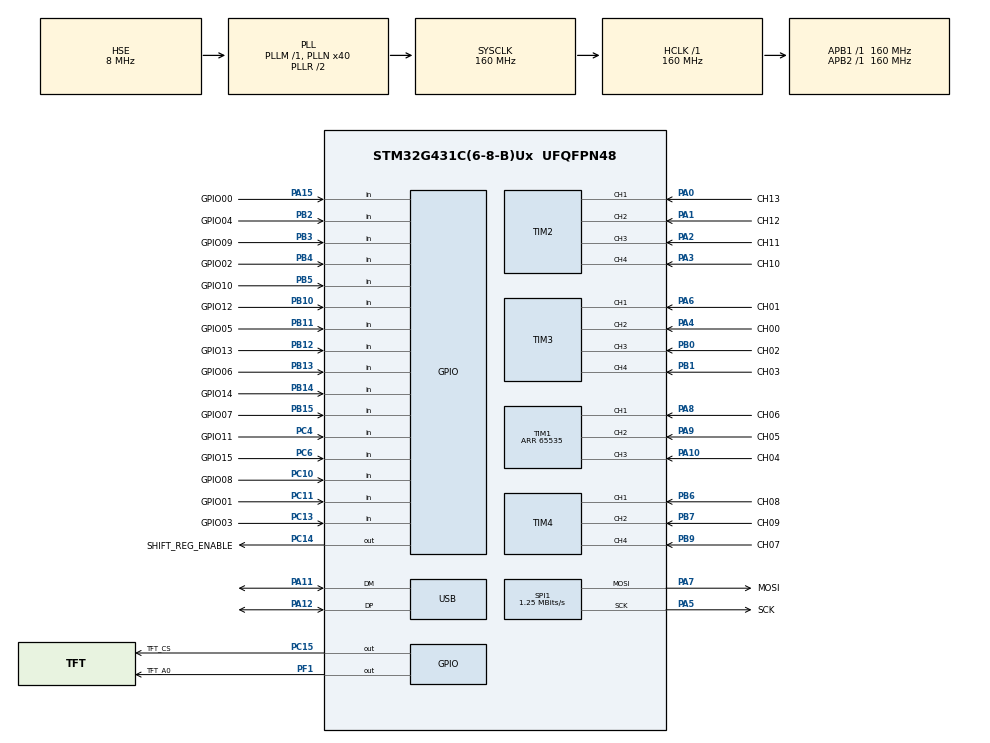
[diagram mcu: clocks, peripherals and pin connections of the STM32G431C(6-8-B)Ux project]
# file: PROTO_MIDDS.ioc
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Mcu.Family=STM32G4
Mcu.Name=STM32G431C(6-8-B)Ux
Mcu.Package=UFQFPN48
NVIC.PriorityGroup=NVIC_PRIORITYGROUP_4
NVIC.TIM1_CC_IRQn=true\:0\:0\:true\:true\:true\:2\:true\:true\:true
NVIC.TIM1_UP_TIM16_IRQn=true\:0\:0\:true\:true\:true\:1\:true\:true\:true
NVIC.TIM2_IRQn=true\:0\:0\:false\:false\:true\:true\:true\:true
NVIC.TIM3_IRQn=true\:0\:0\:false\:false\:true\:true\:true\:true
NVIC.TIM4_IRQn=true\:0\:0\:false\:false\:true\:true\:true\:true
NVIC.USB_LP_IRQn=true\:0\:0\:false\:false\:true\:false\:true\:true
PA0.GPIO_Label=CH13
PA0.GPIO_PuPd=GPIO_PULLDOWN
PA0.GPIO_Speed=GPIO_SPEED_FREQ_VERY_HIGH
PA0.Signal=S_TIM2_CH1
PA1.GPIO_Label=CH12
PA1.GPIO_PuPd=GPIO_PULLDOWN
PA1.GPIO_Speed=GPIO_SPEED_FREQ_VERY_HIGH
PA1.Signal=S_TIM2_CH2
PA10.GPIO_Label=CH04
PA10.GPIO_PuPd=GPIO_PULLDOWN
PA10.GPIO_Speed=GPIO_SPEED_FREQ_VERY_HIGH
PA10.Signal=S_TIM1_CH3
PA11.Mode=Device
PA11.Signal=USB_DM
PA12.Mode=Device
PA12.Signal=USB_DP
PA15.GPIO_Label=GPIO00
PA15.Signal=GPIO_Input
PA2.GPIO_Label=CH11
PA2.GPIO_PuPd=GPIO_PULLDOWN
PA2.GPIO_Speed=GPIO_SPEED_FREQ_VERY_HIGH
PA2.Signal=S_TIM2_CH3
PA3.GPIO_Label=CH10
PA3.GPIO_PuPd=GPIO_PULLDOWN
PA3.GPIO_Speed=GPIO_SPEED_FREQ_VERY_HIGH
PA3.Signal=S_TIM2_CH4
PA4.GPIO_Label=CH00
PA4.GPIO_PuPd=GPIO_PULLDOWN
PA4.GPIO_Speed=GPIO_SPEED_FREQ_VERY_HIGH
PA4.Signal=S_TIM3_CH2
PA5.GPIO_Label=SCK
PA5.GPIO_Speed=GPIO_SPEED_FREQ_VERY_HIGH
PA5.Mode=TX_Only_Simplex_Unidirect_Master
PA5.Signal=SPI1_SCK
PA6.GPIO_Label=CH01
PA6.GPIO_PuPd=GPIO_PULLDOWN
PA6.GPIO_Speed=GPIO_SPEED_FREQ_VERY_HIGH
PA6.Signal=S_TIM3_CH1
PA7.GPIO_Label=MOSI
PA7.Mode=TX_Only_Simplex_Unidirect_Master
PA7.Signal=SPI1_MOSI
PA8.GPIO_Label=CH06
PA8.GPIO_PuPd=GPIO_PULLDOWN
PA8.GPIO_Speed=GPIO_SPEED_FREQ_VERY_HIGH
PA8.Signal=S_TIM1_CH1
PA9.GPIO_Label=CH05
PA9.GPIO_PuPd=GPIO_PULLDOWN
PA9.GPIO_Speed=GPIO_SPEED_FREQ_VERY_HIGH
PA9.Signal=S_TIM1_CH2
PB0.GPIO_Label=CH02
PB0.GPIO_PuPd=GPIO_PULLDOWN
PB0.GPIO_Speed=GPIO_SPEED_FREQ_VERY_HIGH
PB0.Signal=S_TIM3_CH3
PB1.GPIO_Label=CH03
PB1.GPIO_PuPd=GPIO_PULLDOWN
PB1.GPIO_Speed=GPIO_SPEED_FREQ_VERY_HIGH
PB1.Signal=S_TIM3_CH4
PB10.GPIO_Label=GPIO12
PB10.Signal=GPIO_Input
PB11.GPIO_Label=GPIO05
PB11.Signal=GPIO_Input
PB12.GPIO_Label=GPIO13
PB12.Signal=GPIO_Input
PB13.GPIO_Label=GPIO06
PB13.Signal=GPIO_Input
PB14.GPIO_Label=GPIO14
PB14.Signal=GPIO_Input
PB15.GPIO_Label=GPIO07
PB15.Signal=GPIO_Input
PB2.GPIO_Label=GPIO04
PB2.Signal=GPIO_Input
PB3.GPIO_Label=GPIO09
PB3.Signal=GPIO_Input
PB4.GPIO_Label=GPIO02
PB4.Signal=GPIO_Input
PB5.GPIO_Label=GPIO10
PB5.Signal=GPIO_Input
PB6.GPIO_Label=CH08
PB6.GPIO_PuPd=GPIO_PULLDOWN
PB6.GPIO_Speed=GPIO_SPEED_FREQ_VERY_HIGH
PB6.Signal=S_TIM4_CH1
PB7.GPIO_Label=CH09
PB7.GPIO_PuPd=GPIO_PULLDOWN
PB7.GPIO_Speed=GPIO_SPEED_FREQ_VERY_HIGH
PB7.Signal=S_TIM4_CH2
PB9.GPIO_Label=CH07
PB9.GPIO_PuPd=GPIO_PULLDOWN
PB9.GPIO_Speed=GPIO_SPEED_FREQ_VERY_HIGH
PB9.Signal=S_TIM4_CH4
PC10.GPIO_Label=GPIO08
PC10.Signal=GPIO_Input
PC11.GPIO_Label=GPIO01
PC11.Signal=GPIO_Input
PC13.GPIO_Label=GPIO03
PC13.GPIO_PuPd=GPIO_NOPULL
PC13.Signal=GPIO_Input
PC14-OSC32_IN.GPIO_Label=SHIFT_REG_ENABLE
PC14-OSC32_IN.Signal=GPIO_Output
PC15-OSC32_OUT.GPIO_Label=TFT_CS
PC15-OSC32_OUT.Signal=GPIO_Output
PC4.GPIO_Label=GPIO11
PC4.Signal=GPIO_Input
PC6.GPIO_Label=GPIO15
PC6.Signal=GPIO_Input
PF0-OSC_IN.Mode=HSE-External-Clock-Source
PF0-OSC_IN.Signal=RCC_OSC_IN
PF1-OSC_OUT.GPIO_Label=TFT_A0
PF1-OSC_OUT.Signal=GPIO_Output
ProjectManager.HeapSize=0x200
ProjectManager.StackSize=0x400
ProjectManager.TargetToolchain=STM32CubeIDE
RCC.ADC12Freq_Value=160000000
RCC.AHBFreq_Value=160000000
RCC.APB1Freq_Value=160000000
RCC.APB1TimFreq_Value=160000000
RCC.APB2Freq_Value=160000000
RCC.APB2TimFreq_Value=160000000
RCC.CK48CLockSelection=RCC_USBCLKSOURCE_HSI48
RCC.CortexFreq_Value=160000000
RCC.EXTERNAL_CLOCK_VALUE=12288000
RCC.HCLKFreq_Value=160000000
RCC.HSE_VALUE=8000000
RCC.HSI48_VALUE=48000000
RCC.HSICalibrationValue=64
RCC.HSI_VALUE=16000000
RCC.LSE_VALUE=32768
RCC.PLLN=40
RCC.PLLSourceVirtual=RCC_PLLSOURCE_HSE
RCC.SYSCLKFreq_VALUE=160000000
RCC.SYSCLKSource=RCC_SYSCLKSOURCE_PLLCLK
RCC.USBFreq_Value=48000000
RCC.VCOOutputFreq_Value=320000000
SH.S_TIM1_CH1.0=TIM1_CH1,Input_Capture1_from_TI1
SH.S_TIM1_CH2.0=TIM1_CH2,Input_Capture2_from_TI2
SH.S_TIM1_CH3.0=TIM1_CH3,Input_Capture3_from_TI3
SH.S_TIM2_CH1.0=TIM2_CH1,Input_Capture1_from_TI1
SH.S_TIM2_CH2.0=TIM2_CH2,Input_Capture2_from_TI2
SH.S_TIM2_CH3.0=TIM2_CH3,Input_Capture3_from_TI3
SH.S_TIM2_CH4.0=TIM2_CH4,Input_Capture4_from_TI4
SH.S_TIM3_CH1.0=TIM3_CH1,Input_Capture1_from_TI1
SH.S_TIM3_CH2.0=TIM3_CH2,Input_Capture2_from_TI2
SH.S_TIM3_CH3.0=TIM3_CH3,Input_Capture3_from_TI3
SH.S_TIM3_CH4.0=TIM3_CH4,Input_Capture4_from_TI4
SH.S_TIM4_CH1.0=TIM4_CH1,Input_Capture1_from_TI1
SH.S_TIM4_CH2.0=TIM4_CH2,Input_Capture2_from_TI2
SH.S_TIM4_CH4.0=TIM4_CH4,Input_Capture4_from_TI4
SPI1.BaudRatePrescaler=SPI_BAUDRATEPRESCALER_128
SPI1.CalculateBaudRate=1.25 MBits/s
SPI1.DataSize=SPI_DATASIZE_8BIT
SPI1.Direction=SPI_DIRECTION_2LINES
SPI1.FirstBit=SPI_FIRSTBIT_LSB
SPI1.Mode=SPI_MODE_MASTER
SPI1.VirtualType=VM_MASTER
TIM1.AutoReloadPreload=TIM_AUTORELOAD_PRELOAD_DISABLE
TIM1.Channel-Input_Capture1_from_TI1=TIM_CHANNEL_1
TIM1.Channel-Input_Capture2_from_TI2=TIM_CHANNEL_2
TIM1.Channel-Input_Capture3_from_TI3=TIM_CHANNEL_3
TIM1.ICPolarity_CH1=TIM_INPUTCHANNELPOLARITY_BOTHEDGE
TIM1.ICPolarity_CH2=TIM_INPUTCHANNELPOLARITY_BOTHEDGE
TIM1.ICPolarity_CH3=TIM_INPUTCHANNELPOLARITY_BOTHEDGE
TIM1.PeriodNoDither=65535
TIM1.RepetitionCounter=0
TIM1.TIM_MasterOutputTrigger=TIM_TRGO_UPDATE
TIM1.TIM_MasterSlaveMode=TIM_MASTERSLAVEMODE_ENABLE
TIM2.Channel-Input_Capture1_from_TI1=TIM_CHANNEL_1
TIM2.Channel-Input_Capture2_from_TI2=TIM_CHANNEL_2
TIM2.Channel-Input_Capture3_from_TI3=TIM_CHANNEL_3
TIM2.Channel-Input_Capture4_from_TI4=TIM_CHANNEL_4
TIM2.ICPolarity_CH1=TIM_INPUTCHANNELPOLARITY_BOTHEDGE
TIM2.ICPolarity_CH2=TIM_INPUTCHANNELPOLARITY_BOTHEDGE
TIM2.ICPolarity_CH3=TIM_INPUTCHANNELPOLARITY_BOTHEDGE
TIM2.ICPolarity_CH4=TIM_INPUTCHANNELPOLARITY_BOTHEDGE
TIM3.Channel-Input_Capture1_from_TI1=TIM_CHANNEL_1
TIM3.Channel-Input_Capture2_from_TI2=TIM_CHANNEL_2
TIM3.Channel-Input_Capture3_from_TI3=TIM_CHANNEL_3
TIM3.Channel-Input_Capture4_from_TI4=TIM_CHANNEL_4
TIM3.ICPolarity_CH1=TIM_INPUTCHANNELPOLARITY_BOTHEDGE
TIM3.ICPolarity_CH2=TIM_INPUTCHANNELPOLARITY_BOTHEDGE
TIM3.ICPolarity_CH3=TIM_INPUTCHANNELPOLARITY_BOTHEDGE
TIM3.ICPolarity_CH4=TIM_INPUTCHANNELPOLARITY_BOTHEDGE
TIM4.Channel-Input_Capture1_from_TI1=TIM_CHANNEL_1
TIM4.Channel-Input_Capture2_from_TI2=TIM_CHANNEL_2
TIM4.Channel-Input_Capture4_from_TI4=TIM_CHANNEL_4
TIM4.ICPolarity_CH1=TIM_INPUTCHANNELPOLARITY_BOTHEDGE
TIM4.ICPolarity_CH2=TIM_INPUTCHANNELPOLARITY_BOTHEDGE
TIM4.ICPolarity_CH4=TIM_INPUTCHANNELPOLARITY_BOTHEDGE
USB_DEVICE.CLASS_NAME_FS=CDC
USB_DEVICE.VirtualMode=Cdc
USB_DEVICE.VirtualModeFS=Cdc_FS
VP_SYS_VS_DBSignals.Mode=DisableDeadBatterySignals
VP_TIM1_VS_ClockSourceINT.Mode=Internal
VP_TIM2_VS_ClockSourceINT.Mode=Internal
VP_TIM2_VS_ClockSourceITR.Mode=TriggerSource_ITR0
VP_TIM2_VS_ControllerModeReset.Mode=Reset Mode
VP_TIM3_VS_ClockSourceINT.Mode=Internal
VP_TIM3_VS_ClockSourceITR.Mode=TriggerSource_ITR0
VP_TIM3_VS_ControllerModeReset.Mode=Reset Mode
VP_TIM4_VS_ClockSourceINT.Mode=Internal
VP_TIM4_VS_ClockSourceITR.Mode=TriggerSource_ITR0
VP_TIM4_VS_ControllerModeReset.Mode=Reset Mode
VP_USB_DEVICE_VS_USB_DEVICE_CDC_FS.Mode=CDC_FS
board=custom

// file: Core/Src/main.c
/* USER CODE BEGIN Header */
/**
  ******************************************************************************
  * @file           : main.c
  * @brief          : Main program body
  ******************************************************************************
  * @attention
  *
  * Copyright (c) 2024 STMicroelectronics.
  * All rights reserved.
  *
  * This software is licensed under terms that can be found in the LICENSE file
  * in the root directory of this software component.
  * If no LICENSE file comes with this software, it is provided AS-IS.
  *
  ******************************************************************************
  */
/* USER CODE END Header */
#include "main.h"
#include "usb_device.h"

/* USER CODE BEGIN Includes */
#include "MainMCU.h"
/* USER CODE END Includes */

SPI_HandleTypeDef hspi1;

TIM_HandleTypeDef htim1;
TIM_HandleTypeDef htim2;
TIM_HandleTypeDef htim3;
TIM_HandleTypeDef htim4;

void SystemClock_Config(void);
static void MX_GPIO_Init(void);
static void MX_TIM1_Init(void);
static void MX_TIM2_Init(void);
static void MX_TIM3_Init(void);
static void MX_TIM4_Init(void);
static void MX_SPI1_Init(void);
static void MX_NVIC_Init(void);

int main(void)
{

  /* MCU Configuration--------------------------------------------------------*/

  /* Reset of all peripherals, Initializes the Flash interface and the Systick. */
  HAL_Init();

  /* Configure the system clock */
  SystemClock_Config();

  /* Initialize all configured peripherals */
  MX_GPIO_Init();
  MX_TIM1_Init();
  MX_TIM2_Init();
  MX_TIM3_Init();
  MX_TIM4_Init();
  MX_USB_Device_Init();
  MX_SPI1_Init();

  /* Initialize interrupts */
  MX_NVIC_Init();
  /* USER CODE BEGIN 2 */
  initMCU(&htim1, &htim2, &htim3, &htim4, &hspi1);
  /* USER CODE END 2 */

  /* Infinite loop */
  while (1)
  {

    /* USER CODE BEGIN 3 */
    loopMCU();
  }
  /* USER CODE END 3 */
}

void SystemClock_Config(void)
{
  RCC_OscInitTypeDef RCC_OscInitStruct = {0};
  RCC_ClkInitTypeDef RCC_ClkInitStruct = {0};

  /** Configure the main internal regulator output voltage
  */
  HAL_PWREx_ControlVoltageScaling(PWR_REGULATOR_VOLTAGE_SCALE1_BOOST);

  /** Initializes the RCC Oscillators according to the specified parameters
  * in the RCC_OscInitTypeDef structure.
  */
  RCC_OscInitStruct.OscillatorType = RCC_OSCILLATORTYPE_HSI48|RCC_OSCILLATORTYPE_HSE;
  RCC_OscInitStruct.HSEState = RCC_HSE_BYPASS;
  RCC_OscInitStruct.HSI48State = RCC_HSI48_ON;
  RCC_OscInitStruct.PLL.PLLState = RCC_PLL_ON;
  RCC_OscInitStruct.PLL.PLLSource = RCC_PLLSOURCE_HSE;
  RCC_OscInitStruct.PLL.PLLM = RCC_PLLM_DIV1;
  RCC_OscInitStruct.PLL.PLLN = 40;
  RCC_OscInitStruct.PLL.PLLP = RCC_PLLP_DIV2;
  RCC_OscInitStruct.PLL.PLLQ = RCC_PLLQ_DIV2;
  RCC_OscInitStruct.PLL.PLLR = RCC_PLLR_DIV2;
  if (HAL_RCC_OscConfig(&RCC_OscInitStruct) != HAL_OK)
  {
    Error_Handler();
  }

  /** Initializes the CPU, AHB and APB buses clocks
  */
  RCC_ClkInitStruct.ClockType = RCC_CLOCKTYPE_HCLK|RCC_CLOCKTYPE_SYSCLK
                              |RCC_CLOCKTYPE_PCLK1|RCC_CLOCKTYPE_PCLK2;
  RCC_ClkInitStruct.SYSCLKSource = RCC_SYSCLKSOURCE_PLLCLK;
  RCC_ClkInitStruct.AHBCLKDivider = RCC_SYSCLK_DIV1;
  RCC_ClkInitStruct.APB1CLKDivider = RCC_HCLK_DIV1;
  RCC_ClkInitStruct.APB2CLKDivider = RCC_HCLK_DIV1;

  if (HAL_RCC_ClockConfig(&RCC_ClkInitStruct, FLASH_LATENCY_4) != HAL_OK)
  {
    Error_Handler();
  }
}

/**
  * @brief NVIC Configuration.
  * @retval None
  */
static void MX_NVIC_Init(void)
{
  /* TIM1_UP_TIM16_IRQn interrupt configuration */
  HAL_NVIC_SetPriority(TIM1_UP_TIM16_IRQn, 0, 0);
  HAL_NVIC_EnableIRQ(TIM1_UP_TIM16_IRQn);
  /* TIM1_CC_IRQn interrupt configuration */
  HAL_NVIC_SetPriority(TIM1_CC_IRQn, 0, 0);
  HAL_NVIC_EnableIRQ(TIM1_CC_IRQn);
}

static void MX_SPI1_Init(void)
{

  /* SPI1 parameter configuration*/
  hspi1.Instance = SPI1;
  hspi1.Init.Mode = SPI_MODE_MASTER;
  hspi1.Init.Direction = SPI_DIRECTION_2LINES;
  hspi1.Init.DataSize = SPI_DATASIZE_8BIT;
  hspi1.Init.CLKPolarity = SPI_POLARITY_LOW;
  hspi1.Init.CLKPhase = SPI_PHASE_1EDGE;
  hspi1.Init.NSS = SPI_NSS_SOFT;
  hspi1.Init.BaudRatePrescaler = SPI_BAUDRATEPRESCALER_128;
  hspi1.Init.FirstBit = SPI_FIRSTBIT_LSB;
  hspi1.Init.TIMode = SPI_TIMODE_DISABLE;
  hspi1.Init.CRCCalculation = SPI_CRCCALCULATION_DISABLE;
  hspi1.Init.CRCPolynomial = 7;
  hspi1.Init.CRCLength = SPI_CRC_LENGTH_DATASIZE;
  hspi1.Init.NSSPMode = SPI_NSS_PULSE_ENABLE;
  if (HAL_SPI_Init(&hspi1) != HAL_OK)
  {
    Error_Handler();
  }

}

static void MX_TIM1_Init(void)
{

  TIM_ClockConfigTypeDef sClockSourceConfig = {0};
  TIM_MasterConfigTypeDef sMasterConfig = {0};
  TIM_IC_InitTypeDef sConfigIC = {0};

  htim1.Instance = TIM1;
  htim1.Init.Prescaler = 0;
  htim1.Init.CounterMode = TIM_COUNTERMODE_UP;
  htim1.Init.Period = 65535;
  htim1.Init.ClockDivision = TIM_CLOCKDIVISION_DIV1;
  htim1.Init.RepetitionCounter = 0;
  htim1.Init.AutoReloadPreload = TIM_AUTORELOAD_PRELOAD_DISABLE;
  if (HAL_TIM_Base_Init(&htim1) != HAL_OK)
  {
    Error_Handler();
  }
  sClockSourceConfig.ClockSource = TIM_CLOCKSOURCE_INTERNAL;
  if (HAL_TIM_ConfigClockSource(&htim1, &sClockSourceConfig) != HAL_OK)
  {
    Error_Handler();
  }
  if (HAL_TIM_IC_Init(&htim1) != HAL_OK)
  {
    Error_Handler();
  }
  sMasterConfig.MasterOutputTrigger = TIM_TRGO_UPDATE;
  sMasterConfig.MasterOutputTrigger2 = TIM_TRGO2_RESET;
  sMasterConfig.MasterSlaveMode = TIM_MASTERSLAVEMODE_ENABLE;
  if (HAL_TIMEx_MasterConfigSynchronization(&htim1, &sMasterConfig) != HAL_OK)
  {
    Error_Handler();
  }
  sConfigIC.ICPolarity = TIM_INPUTCHANNELPOLARITY_BOTHEDGE;
  sConfigIC.ICSelection = TIM_ICSELECTION_DIRECTTI;
  sConfigIC.ICPrescaler = TIM_ICPSC_DIV1;
  sConfigIC.ICFilter = 0;
  if (HAL_TIM_IC_ConfigChannel(&htim1, &sConfigIC, TIM_CHANNEL_1) != HAL_OK)
  {
    Error_Handler();
  }
  if (HAL_TIM_IC_ConfigChannel(&htim1, &sConfigIC, TIM_CHANNEL_2) != HAL_OK)
  {
    Error_Handler();
  }
  if (HAL_TIM_IC_ConfigChannel(&htim1, &sConfigIC, TIM_CHANNEL_3) != HAL_OK)
  {
    Error_Handler();
  }

}

static void MX_TIM2_Init(void)
{

  TIM_ClockConfigTypeDef sClockSourceConfig = {0};
  TIM_SlaveConfigTypeDef sSlaveConfig = {0};
  TIM_MasterConfigTypeDef sMasterConfig = {0};
  TIM_IC_InitTypeDef sConfigIC = {0};

  htim2.Instance = TIM2;
  htim2.Init.Prescaler = 0;
  htim2.Init.CounterMode = TIM_COUNTERMODE_UP;
  htim2.Init.Period = 4294967295;
  htim2.Init.ClockDivision = TIM_CLOCKDIVISION_DIV1;
  htim2.Init.AutoReloadPreload = TIM_AUTORELOAD_PRELOAD_DISABLE;
  if (HAL_TIM_Base_Init(&htim2) != HAL_OK)
  {
    Error_Handler();
  }
  sClockSourceConfig.ClockSource = TIM_CLOCKSOURCE_INTERNAL;
  if (HAL_TIM_ConfigClockSource(&htim2, &sClockSourceConfig) != HAL_OK)
  {
    Error_Handler();
  }
  if (HAL_TIM_IC_Init(&htim2) != HAL_OK)
  {
    Error_Handler();
  }
  sSlaveConfig.SlaveMode = TIM_SLAVEMODE_RESET;
  sSlaveConfig.InputTrigger = TIM_TS_ITR0;
  if (HAL_TIM_SlaveConfigSynchro(&htim2, &sSlaveConfig) != HAL_OK)
  {
    Error_Handler();
  }
  sMasterConfig.MasterOutputTrigger = TIM_TRGO_RESET;
  sMasterConfig.MasterSlaveMode = TIM_MASTERSLAVEMODE_DISABLE;
  if (HAL_TIMEx_MasterConfigSynchronization(&htim2, &sMasterConfig) != HAL_OK)
  {
    Error_Handler();
  }
  sConfigIC.ICPolarity = TIM_INPUTCHANNELPOLARITY_BOTHEDGE;
  sConfigIC.ICSelection = TIM_ICSELECTION_DIRECTTI;
  sConfigIC.ICPrescaler = TIM_ICPSC_DIV1;
  sConfigIC.ICFilter = 0;
  if (HAL_TIM_IC_ConfigChannel(&htim2, &sConfigIC, TIM_CHANNEL_1) != HAL_OK)
  {
    Error_Handler();
  }
  if (HAL_TIM_IC_ConfigChannel(&htim2, &sConfigIC, TIM_CHANNEL_2) != HAL_OK)
  {
    Error_Handler();
  }
  if (HAL_TIM_IC_ConfigChannel(&htim2, &sConfigIC, TIM_CHANNEL_3) != HAL_OK)
  {
    Error_Handler();
  }
  if (HAL_TIM_IC_ConfigChannel(&htim2, &sConfigIC, TIM_CHANNEL_4) != HAL_OK)
  {
    Error_Handler();
  }

}

static void MX_TIM3_Init(void)
{

  TIM_ClockConfigTypeDef sClockSourceConfig = {0};
  TIM_SlaveConfigTypeDef sSlaveConfig = {0};
  TIM_MasterConfigTypeDef sMasterConfig = {0};
  TIM_IC_InitTypeDef sConfigIC = {0};

  htim3.Instance = TIM3;
  htim3.Init.Prescaler = 0;
  htim3.Init.CounterMode = TIM_COUNTERMODE_UP;
  htim3.Init.Period = 65535;
  htim3.Init.ClockDivision = TIM_CLOCKDIVISION_DIV1;
  htim3.Init.AutoReloadPreload = TIM_AUTORELOAD_PRELOAD_DISABLE;
  if (HAL_TIM_Base_Init(&htim3) != HAL_OK)
  {
    Error_Handler();
  }
  sClockSourceConfig.ClockSource = TIM_CLOCKSOURCE_INTERNAL;
  if (HAL_TIM_ConfigClockSource(&htim3, &sClockSourceConfig) != HAL_OK)
  {
    Error_Handler();
  }
  if (HAL_TIM_IC_Init(&htim3) != HAL_OK)
  {
    Error_Handler();
  }
  sSlaveConfig.SlaveMode = TIM_SLAVEMODE_RESET;
  sSlaveConfig.InputTrigger = TIM_TS_ITR0;
  if (HAL_TIM_SlaveConfigSynchro(&htim3, &sSlaveConfig) != HAL_OK)
  {
    Error_Handler();
  }
  sMasterConfig.MasterOutputTrigger = TIM_TRGO_RESET;
  sMasterConfig.MasterSlaveMode = TIM_MASTERSLAVEMODE_DISABLE;
  if (HAL_TIMEx_MasterConfigSynchronization(&htim3, &sMasterConfig) != HAL_OK)
  {
    Error_Handler();
  }
  sConfigIC.ICPolarity = TIM_INPUTCHANNELPOLARITY_BOTHEDGE;
  sConfigIC.ICSelection = TIM_ICSELECTION_DIRECTTI;
  sConfigIC.ICPrescaler = TIM_ICPSC_DIV1;
  sConfigIC.ICFilter = 0;
  if (HAL_TIM_IC_ConfigChannel(&htim3, &sConfigIC, TIM_CHANNEL_1) != HAL_OK)
  {
    Error_Handler();
  }
  if (HAL_TIM_IC_ConfigChannel(&htim3, &sConfigIC, TIM_CHANNEL_2) != HAL_OK)
  {
    Error_Handler();
  }
  if (HAL_TIM_IC_ConfigChannel(&htim3, &sConfigIC, TIM_CHANNEL_3) != HAL_OK)
  {
    Error_Handler();
  }
  if (HAL_TIM_IC_ConfigChannel(&htim3, &sConfigIC, TIM_CHANNEL_4) != HAL_OK)
  {
    Error_Handler();
  }

}

static void MX_TIM4_Init(void)
{

  TIM_ClockConfigTypeDef sClockSourceConfig = {0};
  TIM_SlaveConfigTypeDef sSlaveConfig = {0};
  TIM_MasterConfigTypeDef sMasterConfig = {0};
  TIM_IC_InitTypeDef sConfigIC = {0};

  htim4.Instance = TIM4;
  htim4.Init.Prescaler = 0;
  htim4.Init.CounterMode = TIM_COUNTERMODE_UP;
  htim4.Init.Period = 65535;
  htim4.Init.ClockDivision = TIM_CLOCKDIVISION_DIV1;
  htim4.Init.AutoReloadPreload = TIM_AUTORELOAD_PRELOAD_DISABLE;
  if (HAL_TIM_Base_Init(&htim4) != HAL_OK)
  {
    Error_Handler();
  }
  sClockSourceConfig.ClockSource = TIM_CLOCKSOURCE_INTERNAL;
  if (HAL_TIM_ConfigClockSource(&htim4, &sClockSourceConfig) != HAL_OK)
  {
    Error_Handler();
  }
  if (HAL_TIM_IC_Init(&htim4) != HAL_OK)
  {
    Error_Handler();
  }
  sSlaveConfig.SlaveMode = TIM_SLAVEMODE_RESET;
  sSlaveConfig.InputTrigger = TIM_TS_ITR0;
  if (HAL_TIM_SlaveConfigSynchro(&htim4, &sSlaveConfig) != HAL_OK)
  {
    Error_Handler();
  }
  sMasterConfig.MasterOutputTrigger = TIM_TRGO_RESET;
  sMasterConfig.MasterSlaveMode = TIM_MASTERSLAVEMODE_DISABLE;
  if (HAL_TIMEx_MasterConfigSynchronization(&htim4, &sMasterConfig) != HAL_OK)
  {
    Error_Handler();
  }
  sConfigIC.ICPolarity = TIM_INPUTCHANNELPOLARITY_BOTHEDGE;
  sConfigIC.ICSelection = TIM_ICSELECTION_DIRECTTI;
  sConfigIC.ICPrescaler = TIM_ICPSC_DIV1;
  sConfigIC.ICFilter = 0;
  if (HAL_TIM_IC_ConfigChannel(&htim4, &sConfigIC, TIM_CHANNEL_1) != HAL_OK)
  {
    Error_Handler();
  }
  if (HAL_TIM_IC_ConfigChannel(&htim4, &sConfigIC, TIM_CHANNEL_2) != HAL_OK)
  {
    Error_Handler();
  }
  if (HAL_TIM_IC_ConfigChannel(&htim4, &sConfigIC, TIM_CHANNEL_4) != HAL_OK)
  {
    Error_Handler();
  }

}

static void MX_GPIO_Init(void)
{
  GPIO_InitTypeDef GPIO_InitStruct = {0};

  /* GPIO Ports Clock Enable */
  __HAL_RCC_GPIOC_CLK_ENABLE();
  __HAL_RCC_GPIOF_CLK_ENABLE();
  __HAL_RCC_GPIOA_CLK_ENABLE();
  __HAL_RCC_GPIOB_CLK_ENABLE();

  /*Configure GPIO pin Output Level */
  HAL_GPIO_WritePin(GPIOC, SHIFT_REG_ENABLE_Pin|TFT_CS_Pin, GPIO_PIN_RESET);

  /*Configure GPIO pin Output Level */
  HAL_GPIO_WritePin(TFT_A0_GPIO_Port, TFT_A0_Pin, GPIO_PIN_RESET);

  /*Configure GPIO pins : GPIO03_Pin GPIO11_Pin GPIO15_Pin GPIO08_Pin
                           GPIO01_Pin */
  GPIO_InitStruct.Pin = GPIO03_Pin|GPIO11_Pin|GPIO15_Pin|GPIO08_Pin
                          |GPIO01_Pin;
  GPIO_InitStruct.Mode = GPIO_MODE_INPUT;
  GPIO_InitStruct.Pull = GPIO_NOPULL;
  HAL_GPIO_Init(GPIOC, &GPIO_InitStruct);

  /*Configure GPIO pins : SHIFT_REG_ENABLE_Pin TFT_CS_Pin */
  GPIO_InitStruct.Pin = SHIFT_REG_ENABLE_Pin|TFT_CS_Pin;
  GPIO_InitStruct.Mode = GPIO_MODE_OUTPUT_PP;
  GPIO_InitStruct.Pull = GPIO_NOPULL;
  GPIO_InitStruct.Speed = GPIO_SPEED_FREQ_LOW;
  HAL_GPIO_Init(GPIOC, &GPIO_InitStruct);

  /*Configure GPIO pin : TFT_A0_Pin */
  GPIO_InitStruct.Pin = TFT_A0_Pin;
  GPIO_InitStruct.Mode = GPIO_MODE_OUTPUT_PP;
  GPIO_InitStruct.Pull = GPIO_NOPULL;
  GPIO_InitStruct.Speed = GPIO_SPEED_FREQ_LOW;
  HAL_GPIO_Init(TFT_A0_GPIO_Port, &GPIO_InitStruct);

  /*Configure GPIO pins : GPIO04_Pin GPIO12_Pin GPIO05_Pin GPIO13_Pin
                           GPIO06_Pin GPIO14_Pin GPIO07_Pin GPIO09_Pin
                           GPIO02_Pin GPIO10_Pin */
  GPIO_InitStruct.Pin = GPIO04_Pin|GPIO12_Pin|GPIO05_Pin|GPIO13_Pin
                          |GPIO06_Pin|GPIO14_Pin|GPIO07_Pin|GPIO09_Pin
                          |GPIO02_Pin|GPIO10_Pin;
  GPIO_InitStruct.Mode = GPIO_MODE_INPUT;
  GPIO_InitStruct.Pull = GPIO_NOPULL;
  HAL_GPIO_Init(GPIOB, &GPIO_InitStruct);

  /*Configure GPIO pin : GPIO00_Pin */
  GPIO_InitStruct.Pin = GPIO00_Pin;
  GPIO_InitStruct.Mode = GPIO_MODE_INPUT;
  GPIO_InitStruct.Pull = GPIO_NOPULL;
  HAL_GPIO_Init(GPIO00_GPIO_Port, &GPIO_InitStruct);

}

void Error_Handler(void)
{
  __disable_irq();
  while (1)
  {
  }
}
